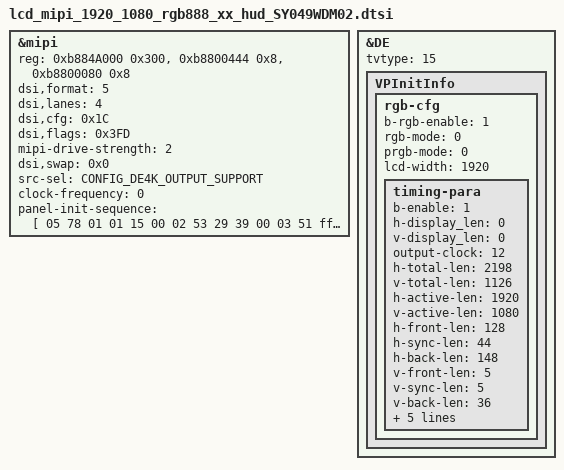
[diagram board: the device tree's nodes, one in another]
&mipi {
	reg = <0xb884A000 0x300>, <0xb8800444 0x8>,<0xb8800080 0x8>;

	/*
	 * MIPI_COLOR_RGB565_0	=	0
	 * MIPI_COLOR_RGB565_1	=	1
	 * MIPI_COLOR_RGB565_2	=	2
	 * MIPI_COLOR_RGB666_0	=	3
	 * MIPI_COLOR_RGB666_1	=	4
	 * MIPI_COLOR_RGB888	=	5
	 */
	dsi,format =<5>;

	dsi,lanes = <4>;

	/*
	 * bit 6:5 :Generic interface read-back Virtual Channel identification.
	 * bit 4 :Enables CRC reception and error reporting.
	 * bit 3 :Enables ECC reception, error correction and reporting
	 * bit 2 :MIPI_Bus_Turn_request.
	 * bit 1 :Enables EOTp reception.
	 * bit 0 :Enables EOTp transmission.
	 */
	dsi,cfg = <0x1C>;

	/* If there is no "dsi,flags", "dsi,flags" = <0x3FD>;
	 * bit 11: Enables the request for an acknowledge response at the end of a fram
	 * bit 10: Enables the transmission of null packets in the HACT period
	 * bit 9:  Enables the transmission of multi video packets in the HACT period
	 * bit 8:  Enables return to Low Power inside HFP period when timing allows.
	 * bit 7:  Enables return to Low Power inside HBP period when timing allows
	 * bit 6:  Enables return to Low Power inside VACT period when timing allows.
	 * bit 5:  Enables return to Low Power inside VFP period when timing allows
	 * bit 4:  Enables return to Low Power inside VBP period when timing allows
	 * bit 3:  Enables return to Low Power inside VSA period when timing allows
	 * bit 2:1 Selects video mode transmission type. 0: Non-burst with Sync pulses; 1: Non-burst with Sync events; 2-3: Burst with Sync pulses.
	 * bit 0:  Enables DPI Video mode transmission.
	 */
	dsi,flags = <0x3FD>;

	/*
	 * 0: MIPI_DRIVE_STRENGTH_MIDIMUN,
	 * 1: MIPI_DRIVE_STRENGTH_MIDDLE,
	 * 2: MIPI_DRIVE_STRENGTH_BIGGER, default
	 * 3: MIPI_DRIVE_STRENGTH_MAXIMUM,
	*/
	mipi-drive-strength = <2>;

	/*
	 * bit 4 : MIPI_DSI_DATA3_LANE_NP_SWAP
	 * bit 3 : MIPI_DSI_DATA2_LANE_NP_SWAP
	 * bit 2 : MIPI_DSI_DATA1_LANE_NP_SWAP
	 * bit 1 : MIPI_DSI_DATA0_LANE_NP_SWAP
	 * bit 0 : MIPI_DSI_CLOCK_LANE_NP_SWAP
	 */

	dsi,swap = <0x0>;
	/*
	 * 0: E_SRC_SEL_FXDE = 0
	 * 1: E_SRC_SEL_4KDE
	 * 2: E_SRC_SEL_HDMI_RX
	 */
	src-sel = <CONFIG_DE4K_OUTPUT_SUPPORT>;
	clock-frequency = <0>;
	//status = "okay";
};

&DE {
	tvtype = <15>;
	VPInitInfo {
		rgb-cfg{
			b-rgb-enable = <1>;
			/*
			 * 0: MODE_PRGB
			 * 1: MODE_SRGB
			 */
			rgb-mode = <0>;
			/*
			 * 0: MODE_PRGB_888_10bit
			 * 1: MODE_PRGB_666
			 */
			prgb-mode = <0>;
			lcd-width = <1920>;
			timing-para {
				/* bool type, 0 or 1*/
				b-enable = <1>;

				h-display_len = <0>;
				v-display_len = <0>;

				/*
				 * VPO_RGB_CLOCK_27M = 1,
				 * VPO_RGB_CLOCK_33M = 2,
				 * VPO_RGB_CLOCK_49M = 3,
				 * VPO_RGB_CLOCK_66M = 4,
				 * VPO_RGB_CLOCK_74M = 5,
				 * VPO_RGB_CLOCK_85M = 6,
				 * VPO_RGB_CLOCK_108M = 7,
				 * VPO_RGB_CLOCK_6_6M = 8,
				 * VPO_RGB_CLOCK_9M = 9,
				 * VPO_RGB_CLOCK_39_6M = 10,
				 * VPO_RGB_CLOCK_74_25M = 11,
				 * VPO_RGB_CLOCK_148_5M = 12,
				 * VPO_RGB_CLOCK_54M = 13,
				 * VPO_RGB_CLOCK_132M = 14,//H1600
				 * VPO_RGB_CLOCK_297M = 15,//H1600 only De4k
				 * VPO_RGB_CLOCK_DPLL = 0xFF,//H1600
				*/
				output-clock = <12>;

				h-total-len = <2198>;
				v-total-len = <1126>;

				h-active-len = <1920>;
				v-active-len = <1080>;

				h-front-len = <128>;
				h-sync-len = <44>;
				h-back-len = <148>;

				v-front-len = <5>;
				v-sync-len = <5>;
				v-back-len = <36>;

				/* bool type, 0 or 1*/
				h-sync-level = <0>;
				/* bool type, 0 or 1*/
				v-sync-level = <0>;

				/* bool type, 0 or 1*/
				active-polarity = <1>;
				frame-rate = <60000>;

				/*
				31	De_dig_pll_en
				25:16	DE_DIG_PLL_M_ctrl
				13:8	DE_DIG_PLL_N_ctrl
				5:0	DE_DIG_PLL_L_ctrl
				de_digpll_clock = 24 *(M+1)/((N+1)*(L+1))
				*/
				dpll-clock-reg-value = <0x0>;
			};
		};
	};
};

&mipi{
	panel-init-sequence = [
		05 78 01 01
		15 00 02 53 29
		39 00 03 51 ff 01
		15 00 02 30 00
		39 00 07 80 00 E0 E0 0E 00 31
		39 00 08 81 03 04 00 29 00 05 00
		39 00 08 82 03 04 00 29 00 05 01
		15 00 02 35 00
		15 00 02 26 20
		39 00 03 f0 AA 11
		15 00 02 C0 00
		39 00 09 C2 03 FF 03 FF 03 FF 03 FF
		39 00 03 F0 AA 12
		39 00 03 BF 37 A9
		39 00 03 FF 5A 80
		15 00 02 65 2F
		15 00 02 F2 01
		39 00 03 FF 5A 81
		15 00 02 65 05
		15 00 02 F2 22
		15 00 02 65 0A
		15 00 02 F2 00
		15 00 02 65 17
		39 00 0e F9 5E 62 66 6A 6F 73 77 7B 7F 84 88 8C 90
		05 78 01 11
		05 78 01 29
		39 00 03 F0 aA 11
		15 78 02 c0 ff
	];
};
